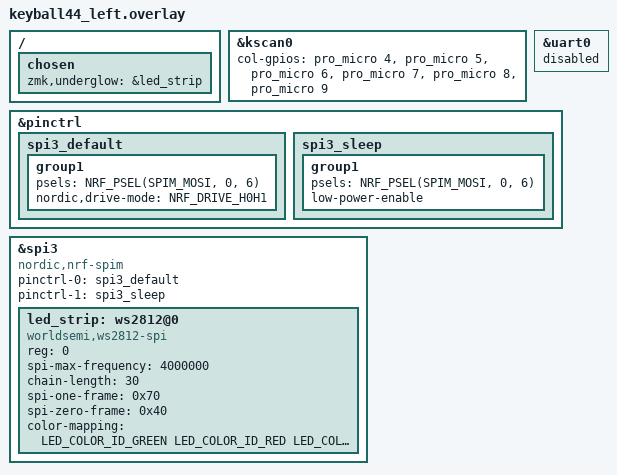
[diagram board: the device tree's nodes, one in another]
/*
 * Copyright (c) 2020 ZMK Contributors
 *
 * SPDX-License-Identifier: MIT
 */

#include <dt-bindings/led/led.h>
#include "keyball44.dtsi"

&kscan0 {
    col-gpios =
        <&pro_micro 4 GPIO_ACTIVE_HIGH>,
        <&pro_micro 5 GPIO_ACTIVE_HIGH>,
        <&pro_micro 6 GPIO_ACTIVE_HIGH>,
        <&pro_micro 7 GPIO_ACTIVE_HIGH>,
        <&pro_micro 8 GPIO_ACTIVE_HIGH>,
        <&pro_micro 9 GPIO_ACTIVE_HIGH>;
};

/* Keyball44 KiCad: LED DIN on Pro Micro TX (D1) = P0.06. */
&uart0 {
    status = "disabled";
};

&pinctrl {
    spi3_default: spi3_default {
        group1 {
            psels = <NRF_PSEL(SPIM_MOSI, 0, 6)>;
            nordic,drive-mode = <NRF_DRIVE_H0H1>;
        };
    };

    spi3_sleep: spi3_sleep {
        group1 {
            psels = <NRF_PSEL(SPIM_MOSI, 0, 6)>;
            low-power-enable;
        };
    };
};

&spi3 {
    compatible = "nordic,nrf-spim";
    status = "okay";

    pinctrl-0 = <&spi3_default>;
    pinctrl-1 = <&spi3_sleep>;
    pinctrl-names = "default", "sleep";

    led_strip: ws2812@0 {
        compatible = "worldsemi,ws2812-spi";
        reg = <0>;
        spi-max-frequency = <4000000>;
        chain-length = <30>;
        spi-one-frame = <0x70>;
        spi-zero-frame = <0x40>;
        color-mapping = <LED_COLOR_ID_GREEN
                         LED_COLOR_ID_RED
                         LED_COLOR_ID_BLUE>;
    };
};

/ {
    chosen {
        zmk,underglow = &led_strip;
    };
};
